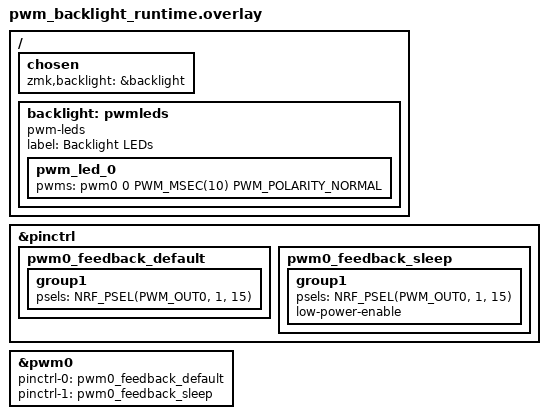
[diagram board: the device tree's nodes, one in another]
#include <zephyr/dt-bindings/pwm/pwm.h>

&pinctrl {
    pwm0_feedback_default: pwm0_feedback_default {
        group1 {
            psels = <NRF_PSEL(PWM_OUT0, 1, 15)>;
        };
    };

    pwm0_feedback_sleep: pwm0_feedback_sleep {
        group1 {
            psels = <NRF_PSEL(PWM_OUT0, 1, 15)>;
            low-power-enable;
        };
    };
};

/ {
    chosen {
        zmk,backlight = &backlight;
    };

    backlight: pwmleds {
        compatible = "pwm-leds";
        label = "Backlight LEDs";

        pwm_led_0: pwm_led_0 {
            pwms = <&pwm0 0 PWM_MSEC(10) PWM_POLARITY_NORMAL>;
        };
    };
};

&pwm0 {
    status = "okay";
    pinctrl-0 = <&pwm0_feedback_default>;
    pinctrl-1 = <&pwm0_feedback_sleep>;
    pinctrl-names = "default", "sleep";
};
